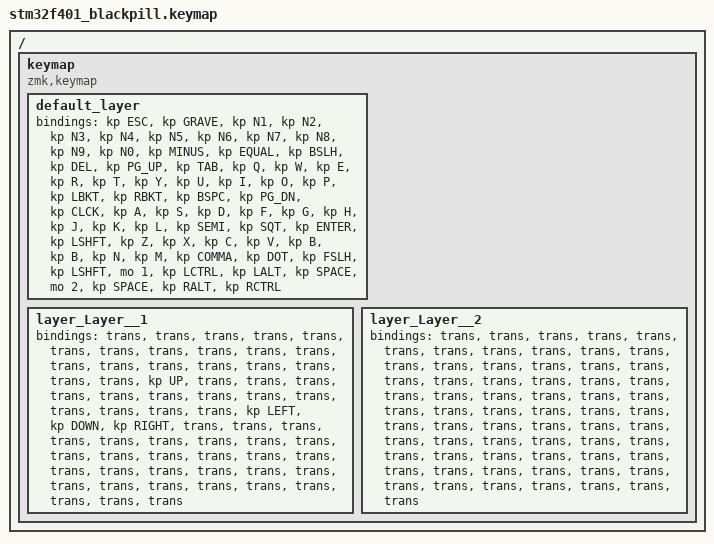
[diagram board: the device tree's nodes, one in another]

/*
 * Copyright (c) 2020 The ZMK Contributors
 *
 * SPDX-License-Identifier: MIT
 */


/* THIS FILE WAS GENERATED!
 *
 * This file was generated automatically. You may or may not want to
 * edit it directly.
 */

#include <behaviors.dtsi>
#include <dt-bindings/zmk/keys.h>

/ {
    keymap {
        compatible = "zmk,keymap";


        default_layer {
            bindings = <
 &kp ESC  &kp GRAVE  &kp N1  &kp N2  &kp N3  &kp N4            &kp N5  &kp N6  &kp N7  &kp N8  &kp N9  &kp N0  &kp MINUS  &kp EQUAL  &kp BSLH  &kp DEL  &kp PG_UP  &kp TAB   &kp Q   &kp W   &kp E   &kp R   &kp T   &kp Y   &kp U   &kp I   &kp O   &kp P  &kp LBKT  &kp RBKT  &kp BSPC  &kp PG_DN  &kp CLCK   &kp A   &kp S   &kp D   &kp F   &kp G   &kp H   &kp J   &kp K   &kp L  &kp SEMI  &kp SQT  &kp ENTER  &kp LSHFT   &kp Z   &kp X   &kp C   &kp V   &kp B   &kp B   &kp N   &kp M  &kp COMMA  &kp DOT  &kp FSLH  &kp LSHFT   &mo 1  &kp LCTRL  &kp LALT  &kp SPACE   &mo 2  &kp SPACE  &kp RALT  &kp RCTRL
            >;
        };

        layer_Layer__1 {
            bindings = <
 &trans  &trans  &trans  &trans  &trans  &trans            &trans  &trans  &trans  &trans  &trans  &trans  &trans  &trans  &trans  &trans  &trans  &trans  &trans  &kp UP  &trans  &trans  &trans  &trans  &trans  &trans  &trans  &trans  &trans  &trans  &trans  &trans  &trans  &kp LEFT  &kp DOWN  &kp RIGHT  &trans  &trans  &trans  &trans  &trans  &trans  &trans  &trans  &trans  &trans  &trans  &trans  &trans  &trans  &trans  &trans  &trans  &trans  &trans  &trans  &trans  &trans  &trans  &trans  &trans  &trans  &trans  &trans  &trans  &trans
            >;
        };

        layer_Layer__2 {
            bindings = <
 &trans  &trans  &trans  &trans  &trans  &trans            &trans  &trans  &trans  &trans  &trans  &trans  &trans  &trans  &trans  &trans  &trans  &trans  &trans  &trans  &trans  &trans  &trans  &trans  &trans  &trans  &trans  &trans  &trans  &trans  &trans  &trans  &trans  &trans  &trans  &trans  &trans  &trans  &trans  &trans  &trans  &trans  &trans  &trans  &trans  &trans  &trans  &trans  &trans  &trans  &trans  &trans  &trans  &trans  &trans  &trans  &trans  &trans  &trans  &trans  &trans  &trans  &trans  &trans  &trans  &trans
            >;
        };

    };
};
